# HSM_HSM_PKA_CE010000h register map
Vendor: Texas Instruments
Peripheral module from a debugger description file (folder AM263X).
Registers are 32-bit, read-write, reset 0x0 unless marked. A register's access mark holds for its fields unless they carry their own. Offsets are as the file gives them; lines under a group give offsets from that group; [hi:lo] are bit positions; {n}, {i} and the like mark numbered series; 'fields as' and 'values as' point back to an identical list; <NAME> marks a mode.

## HSM_PKA
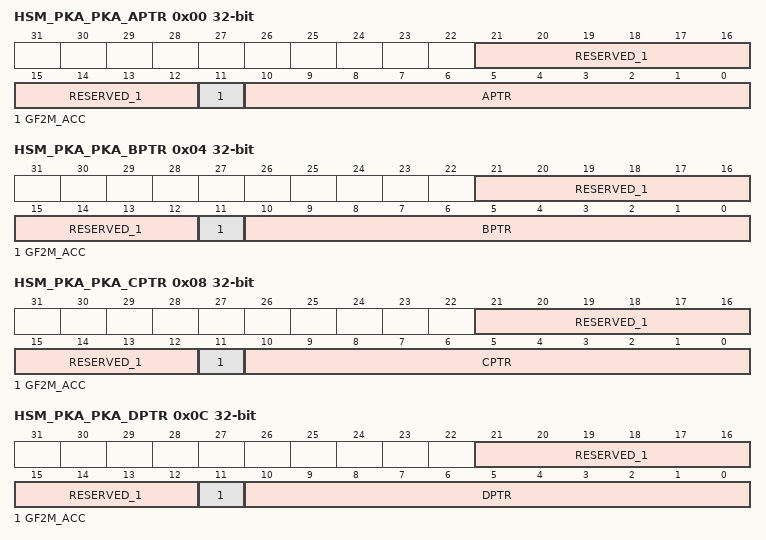
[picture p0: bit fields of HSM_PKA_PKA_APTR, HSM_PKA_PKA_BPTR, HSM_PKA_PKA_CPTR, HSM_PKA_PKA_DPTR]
0x00 HSM_PKA_PKA_APTR access per field — A operand address offset.
  [21:12] RESERVED_1 wo — Set to zero on Write, ignore on Read.
  [11] GF2M_ACC rw — When set, this bit specifies that Vector A is located within the operand registers of the GF2m Engine.
  [10:0] APTR rw — These bits specify the location of Vector A within the PKA RAM. Vectors are identified through the location of their least-significant 32-bit word. Note that bit [0] must be zero to ensure that the vector starts at an 8-byte boundary.
0x04 HSM_PKA_PKA_BPTR access per field — B operand address offset.
  [21:12] RESERVED_1 wo — Set to zero on Write, ignore on Read.
  [11] GF2M_ACC rw — When set, this bit specifies that Vector B is located within the operand registers of the GF2m Engine.
  [10:0] BPTR rw — These bits specify the location of Vector B within the PKA RAM. Vectors are identified through the location of their least-significant 32-bit word. Note that bit [0] must be zero to ensure that the vector starts at an 8-byte boundary.
0x08 HSM_PKA_PKA_CPTR access per field — C operand/result address offset.
  [21:12] RESERVED_1 wo — Set to zero on Write, ignore on Read.
  [11] GF2M_ACC rw — When set, this bit specifies that Vector C is located within the operand registers of the GF2m Engine.
  [10:0] CPTR rw — These bits specify the location of Vector C within the PKA RAM. Vectors are identified through the location of their least-significant 32-bit word. Note that bit [0] must be zero to ensure that the vector starts at an 8-byte boundary.
0x0C HSM_PKA_PKA_DPTR access per field — D operand/result address offset.
  [21:12] RESERVED_1 wo — Set to zero on Write, ignore on Read.
  [11] GF2M_ACC rw — When set, this bit specifies that Vector D is located within the operand registers of the GF2m Engine.
  [10:0] DPTR rw — These bits specify the location of Vector D within the PKA RAM. Vectors are identified through the location of their least-significant 32-bit word. Note that bit [0] must be zero to ensure that the vector starts at an 8-byte boundary.
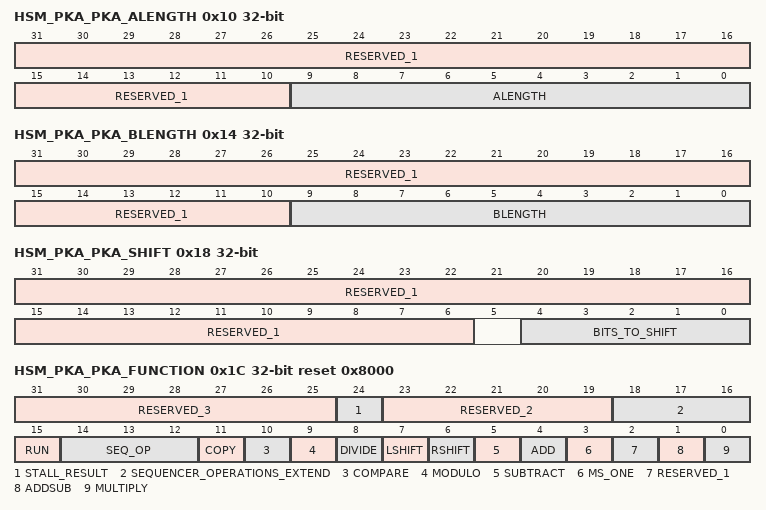
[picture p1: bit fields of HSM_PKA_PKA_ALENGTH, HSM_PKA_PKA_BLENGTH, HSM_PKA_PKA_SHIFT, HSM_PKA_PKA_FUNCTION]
0x10 HSM_PKA_PKA_ALENGTH access per field — Length of A operand.
  [31:10] RESERVED_1 wo — Set to zero on Write, ignore on Read.
  [9:0] ALENGTH rw — This register specifies the length [in 32-bit words] of Vector A.
0x14 HSM_PKA_PKA_BLENGTH access per field — Length of B operand.
  [31:10] RESERVED_1 wo — Set to zero on Write, ignore on Read.
  [9:0] BLENGTH rw — This register specifies the length [in 32-bit words] of Vector A.
0x18 HSM_PKA_PKA_SHIFT access per field — Bits to shift.
  [31:6] RESERVED_1 wo — Set to zero on Write, ignore on Read.
  [4:0] BITS_TO_SHIFT rw — This register specifies the number of bits to shift the input vector [in the range 0- 31] during a Rshift or Lshift operation
0x1C HSM_PKA_PKA_FUNCTION access per field reset 0x8000 — Function code, Run control/status, Stall Result control.
  [31:25] RESERVED_3 wo — Set to zero on Write, ignore on Read
  [24] STALL_RESULT rw — When written with a1b updating of the PKA_COMPARE, PKA_MSW and PKA_DIVMSW registers, as well as resetting the Run bit is stalled beyond the point that a running operation is actually finished. Use this to allow software enough time to read results from a previous operation when the newly started operation is known to take only a short amount of time. If a result is waiting, the result registers is updated and the Run bit is reset in the clock cycle following Writing the Stall Result bit back to0b The Stall result function may only be used for basic PKCP operations
  [23:19] RESERVED_2 wo — Set to zero on Write, ignore on Read.
  [18:16] SEQUENCER_OPERATIONS_EXTEND rw — These bits are an extend of bits [14:12] to select the complex Sequencer operation to perform
  [15] RUN rw — The host sets this bit to instruct the PKA module to begin processing the basic PKCP or complex Sequencer operation. This bit is reset low automatically when the operation is complete. The complement of this bit is available as interrupt see sections 5.6.5 and 5.6.6. After a reset, the Run bit is always set to1b Depending on the configuration, Program ROM or Program RAM, the following applies: Program ROM The first Sequencer instruction sets the bit to0b This is done immediately after the hardware reset is released. Program RAM The Sequencer needs to set the bit to0b As a valid firmware may not have been loaded, the Sequencer is held in software reset after the hardware reset is released [the Reset bit in PKA_SEQ_CRTL is set to1b. After the FW image is loaded and the Reset bit is cleared, the Sequencer starts to execute the FW. The first instruction clears the Run bit. In both cases a few clock cycles are needed before the first instruction is executed and the Run bit state has been propagated
  [14:12] SEQ_OP rw — These bits in combination with bits [18:16] select the complex Sequencer operation to perform
  [11] COPY rw — Perform copy operation.
  [10] COMPARE rw — Perform compare operation
  [9] MODULO rw — Perform modulo operation.
  [8] DIVIDE rw — Perform divide operation.
  [7] LSHIFT rw — Perform left shift operation.
  [6] RSHIFT rw — Perform right shift operation
  [5] SUBTRACT rw — Perform subtract operation
  [4] ADD rw — Perform add operation
  [3] MS_ONE rw — Loads the location of the Most Significant one bit within the result word indicated in the PKA_MSW register into bits [4:0] of the PKA_DIVMSW register - can only be used with basic PKCP operations8 , except for Divide, Modulo and Compare.
  [2] RESERVED_1 wo — Set to zero on Write, ignore on Read
  [1] ADDSUB rw — Perform combined Add/Subtract operation
  [0] MULTIPLY rw — Perform multiply operation.
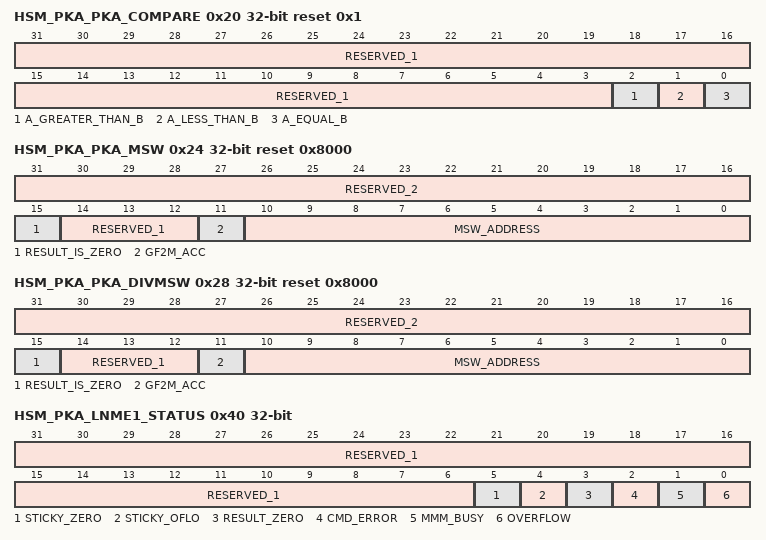
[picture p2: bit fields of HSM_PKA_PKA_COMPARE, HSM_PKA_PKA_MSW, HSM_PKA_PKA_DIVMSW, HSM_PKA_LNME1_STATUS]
0x20 HSM_PKA_PKA_COMPARE access per field reset 0x1 — Result of compare.
  [31:3] RESERVED_1 wo — Ignore on Read.
  [2] A_GREATER_THAN_B ro — Vector_A is greater than Vector_B.
  [1] A_LESS_THAN_B ro — Vector_A is less than Vector_B.
  [0] A_EQUAL_B ro — Vector_A is equal to Vector_B.
0x24 HSM_PKA_PKA_MSW access per field reset 0x8000 — MS non-zero word address.
  [31:16] RESERVED_2 wo — Ignore on Read.
  [15] RESULT_IS_ZERO ro — The result vector is all zeroes; ignore the address returned in bits [10:0].
  [14:12] RESERVED_1 wo — Ignore on Read.
  [11] GF2M_ACC ro — When set, this bit specifies that the result vector is located within the operand registers of the GF2m Engine.
  [10:0] MSW_ADDRESS ro — Address of the most significant non-zero 32-bit word of the result vector in PKA RAM.
0x28 HSM_PKA_PKA_DIVMSW access per field reset 0x8000 — MS non-zero word address for remainder (MOD and DIV ops).
  [31:16] RESERVED_2 wo — Ignore on Read.
  [15] RESULT_IS_ZERO ro — The result vector is all zeroes; ignore the address returned in bits [10:0].
  [14:12] RESERVED_1 wo — Ignore on Read.
  [11] GF2M_ACC ro — When set, this bit specifies that the result vector is located within the operand registers of the GF2m Engine.
  [10:0] MSW_ADDRESS ro — The description of the bits in this field depends on the value of the MS one bit in PKA_FUNCTION register. When MS one bit is0b Msw_Address[10:0] Address of the most significant non-zero 32-bit word of the Remainder result vector in PKA RAM. When MS one bit is1b Msw_bit_position[4:0] Reports the bit number of the most significant non-zero bit in the most significant non-zero word in PKA RAM. Remaining bits [10:5] are reserved.
0x40 HSM_PKA_LNME1_STATUS access per field — LNME 1 status register.
  [31:6] RESERVED_1 wo — Bits should be written with 0 and should be ignored on a read.
  [5] STICKY_ZERO rw — Read/write, reset value0b set to1bby hardware when the result of an MMM* or EXP operation is equal to zero or equal to the modulus N. Updated at the end of an operation [setonly], not cleared to0bby hardware on start of any operation [must be cleared by whoever is controlling the LNME]. Updating this bit is optional when requesting a 'fast ' MMM3A operation via the LNME_FAST_MMM register
  [4] STICKY_OFLO rw — Read/write, reset value0b set to1bby hardware when the result of an MMM* or EXP operation is equal to- or greater than the modulus N. Updated at the end of an operation [setonly], not cleared to0bby hardware on start of any operation [must be cleared by whoever is controlling the LNME]. Updating this bit is optional when requesting a 'fast ' MMM3A operation via the LNME_FAST_MMM register.
  [3] RESULT_ZERO rw — Read/write, reset value0b set to1bby hardware when the result of an MMM* or EXP operation is equal to zero or equal to the modulus N. Updated at the end of an operation, automatically cleared to0bby hardware on start of any operation
  [2] CMD_ERROR rw — Read/write, reset value0b set to1bby hardware when trying to start multiple operations in one command, automatically cleared to0bby hardware on start of any [legal] operation
  [1] MMM_BUSY rw — Read/write, reset value0b set to1bby hardware when the LNME executes an MMM* or EXP operation [cannot be written to0bduring execution of an operation]. Automatically cleared to0bby hardware when finishing an operation. The LNME interrupt is the complement of this bit and can be controlled directly for testing purposes when no actual operation is busy.
  [0] OVERFLOW rw — Read/write, reset value0b set to1bby hardware when the result of an MMM* or EXP operation is equal to- or greater than the modulus N. Updated at the end of an operation, automatically cleared to0bby hardware on start of any operation
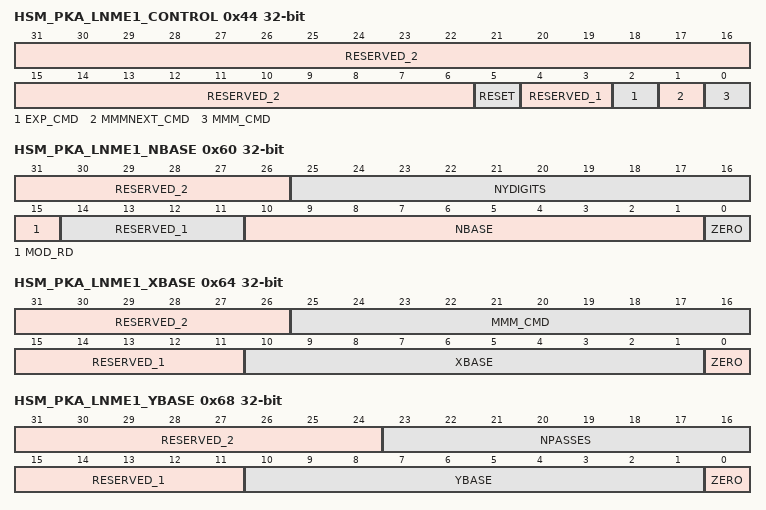
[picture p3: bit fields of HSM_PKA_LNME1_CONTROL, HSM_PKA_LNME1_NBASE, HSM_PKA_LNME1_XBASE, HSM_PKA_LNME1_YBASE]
0x44 HSM_PKA_LNME1_CONTROL access per field — LNME 1 control register (no SW reset).
  [31:6] RESERVED_2 wo — Bits should be written with 0 and should be ignored on a read.
  [5] RESET rw — Set-only, reset value0b When set to1b the LNME is reset and all internal storage locations are flushed [including the LNME FIFO RAM[s]], cleared to0bby hardware at the end of the operation. This command has priority over the MMM* and EXP commands and can abort those in mid-execution. Note: Bit [5] is 'Reserved ' in the LNME1_CONTROL register. For a dual LNME, the 'reset ' bit in the LNME0_CONTROL register controls the software reset in both LNMEs
  [4:3] RESERVED_1 wo — Bits should be written with 0 and should be ignored on a read. For backward compatibility, these bits are actually connected to flip-flops.
  [2] EXP_CMD rw — Set-only, reset value0b When set to1b the LNME starts an EXP operation; cleared to0bby hardware at the end of the operation or when executing a RESET command
  [1] MMMNEXT_CMD rw — Set-only, reset value0b When set to1b the LNME starts an MMMNEXT operation; cleared to0bby hardware at the end of the operation or when executing a RESET command. Note: Setting bits [1] and [0] at the same time starts an MMM3A operation, whereby the result of the MMM operation is written to the offset in PKA data RAM specified by the bbase field in the LNME*_BBASE register. These bits are cleared to 0 by hardware at the end of the operation or when executing a RESET command.
  [0] MMM_CMD rw — Set-only, reset value0b When set to1b the LNME starts an MMM operation; cleared to0bby hardware at the end of the operation or when executing a RESET command.
0x60 HSM_PKA_LNME1_NBASE access per field — N-Operand BASE Address, Y-Operand and N-Operand 32-bit 'Digits '
  [31:26] RESERVED_2 wo — Bits should be written with 0 and should be ignored on a read
  [25:16] NYDIGITS rw — Y-Operand and N-Operand 32-bit'digits' [offset by 1]. Also used for X-operand length in an EXP operation. Minimum value is 0 [for 32 bit operands], maximum value is 12810 [for4128bit operands, actually4096'real ' data bits plus 32 bits to handle inputs and results higher than the4096bits modulus value].
  [15] MOD_RD rw — Setting this bit to1bindicates that the modulus should be read from the GF2m Engine 's GF2M_OPERAND_A_0..15 [bits [511:0]] and GF2M_OPERAND_B_0..7 [bits [767:512]] registers. Note: When this bit is set, the nbase field contents become 'don 't care '.
  [14:11] RESERVED_1 wo — Bits should be written with 0 and should be ignored on a read.
  [10:1] NBASE rw — N-Operand Base Address.
  [0] ZERO ro — Bit [0] is forced to 0 to locate the first 32 bits word at a 64 bit word boundary.
0x64 HSM_PKA_LNME1_XBASE access per field — X-Operand BASE Address, X-Operand 32-bit 'Digits '.
  [31:26] RESERVED_2 wo — Bits should be written with 0 and should be ignored on a read.
  [25:16] MMM_CMD rw — X-Operand 32-bit'digits' [offset by 1], used for MMM* operations only. Minimum value is 0 [for 32 bit X operands], maximum value is 12811 [for4128bit X operands, actually4096'real ' data bits plus 2 extra bits to handle X inputs up to four times the4096bits modulus value, plus 30 dummy data bits to fill out the last word which should all be 0].
  [15:11] RESERVED_1 wo — Bits should be written with 0 and should be ignored on a read.
  [10:1] XBASE rw — X-Operand Base Address.
  [0] ZERO ro — Bit [0] is forced to 0 to locate the first 32 bits word at a 64 bit word boundary.
0x68 HSM_PKA_LNME1_YBASE access per field — Y-Operand BASE Address, MMM Passes.
  [31:24] RESERVED_2 wo — Bits should be written with 0 and should be ignored on a read.
  [23:16] NPASSES rw — MMM passes. Minimum value is 0 [for ONE pass], maximum value is 255 for 256 passes.
  [15:11] RESERVED_1 wo — Bits should be written with 0 and should be ignored on a read.
  [10:1] YBASE rw — Y-Operand Base Address.
  [0] ZERO ro — Bit [0] is forced to 0 to locate the first 32 bits word at a 64 bit word boundary.
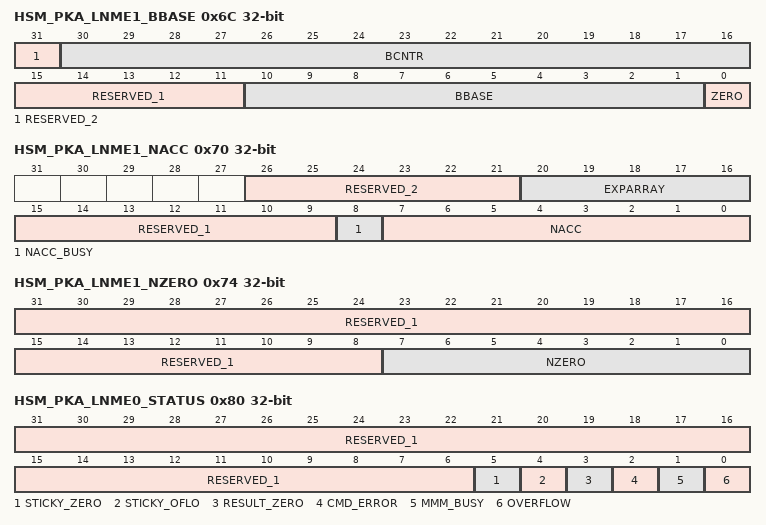
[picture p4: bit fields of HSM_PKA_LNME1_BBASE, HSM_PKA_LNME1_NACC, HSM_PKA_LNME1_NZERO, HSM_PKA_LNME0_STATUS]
0x6C HSM_PKA_LNME1_BBASE access per field — B-Operand BASE Address, B-Operand Bit Count.
  [31] RESERVED_2 wo — Bits should be written with 0 and should be ignored on a read.
  [30:16] BCNTR rw — B-Operand Bit Count. Minimum value is 0 for an exponent length of 2 bits, maximum value is 409513 for an exponent of4097bits [to allow exponent blinding]. If no exponent blinding is used the exponent would normally be smaller than the modulus. Note that the most significant B operand bit need not be stored in memory and is always assumed to be1b
  [15:11] RESERVED_1 wo — Bits should be written with 0 and should be ignored on a read.
  [10:1] BBASE rw — B-Operand BASE Address.
  [0] ZERO ro — Bit [0] is forced to 0 to locate the first 32 bits word at a 64 bit word boundary.
0x70 HSM_PKA_LNME1_NACC access per field — N ', N ' calculation busy flag, exponent array size for EXP.
  [26:21] RESERVED_2 wo — Bits should be written with 0 and should be ignored on a read.
  [20:16] EXPARRAY rw — Exponent Array. A minimum [default] value of 0 indicates that there is only odd power: AR mod N. This is the value of exparray when exponent re-coding is not used. A maximum value of 31 indicates 32 odd powers can be used for exponent re-coding, this includes A1R mod N as the first 'odd power '.
  [15:9] RESERVED_1 wo — Bits should be written with 0 and should be ignored on a read.
  [8] NACC_BUSY rw — Reset-only - nacc Calculation Busy, set to1bduring 8 clock cycles after Writing nzero in LNME*_NZERO while nacc is being calculated. During this time, operation starts are stalled. Writing this bit with0baborts the calculation but can leave nacc in an unknown state [Writing NACC while resetting nacc_busy prevents this].
  [7:0] NACC rw — N Accent. Any odd [bit [0] is1b 8 bit value can be loaded here [result of calculation]. Automatically loaded with calculated value after Writing nzero in LNME*_NZERO.
0x74 HSM_PKA_LNME1_NZERO access per field — Lowest byte of N-Operand for N ' calculation.
  [31:8] RESERVED_1 wo — Bits should be written with 0 and should be ignored on a read.
  [7:0] NZERO rw — N vector Byte 0. Any odd [bit [0] is1b 8 bit value can be loaded here. Writing starts the nacc calculation automatically.
0x80 HSM_PKA_LNME0_STATUS access per field — LNME 0 status register.
  fields as HSM_PKA_LNME1_STATUS
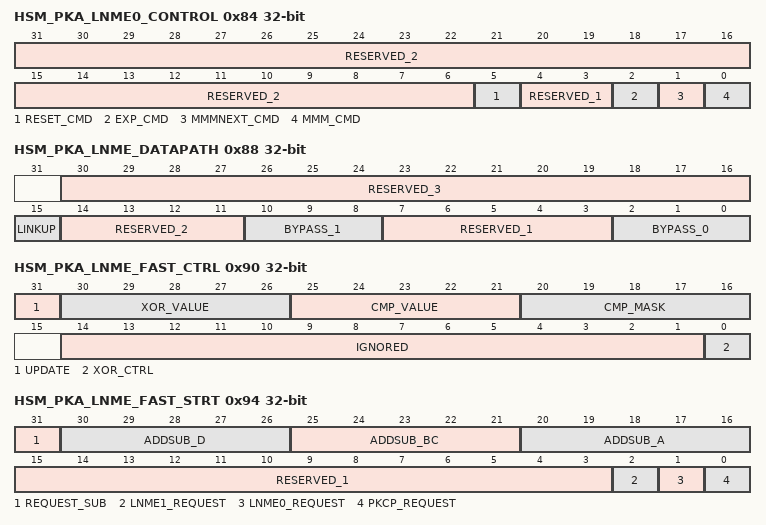
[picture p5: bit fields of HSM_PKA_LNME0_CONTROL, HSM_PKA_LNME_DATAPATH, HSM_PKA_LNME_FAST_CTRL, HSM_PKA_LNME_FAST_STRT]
0x84 HSM_PKA_LNME0_CONTROL access per field — LNME 0 control register.
  [31:6] RESERVED_2 wo — Bits should be written with 0 and should be ignored on a read.
  [5] RESET_CMD rw — Set-only, reset value0b When set to1b the LNME is reset and all internal storage locations are flushed [including the LNME FIFO RAM[s]], cleared to0bby hardware at the end of the operation. This command has priority over the MMM* and EXP commands and can abort those in mid-execution. Note: Bit [5] is 'Reserved ' in the LNME1_CONTROL register. For a dual LNME, the 'reset ' bit in the LNME0_CONTROL register controls the software reset in both LNMEs
  [4:3] RESERVED_1 wo — Bits should be written with 0 and should be ignored on a read. For backward compatibility, these bits are actually connected to flip-flops.
  [2] EXP_CMD rw — Set-only, reset value0b When set to1b the LNME starts an EXP operation; cleared to0bby hardware at the end of the operation or when executing a RESET command
  [1] MMMNEXT_CMD rw — Set-only, reset value0b When set to1b the LNME starts an MMMNEXT operation; cleared to0bby hardware at the end of the operation or when executing a RESET command. Note: Setting bits [1] and [0] at the same time starts an MMM3A operation, whereby the result of the MMM operation is written to the offset in PKA data RAM specified by the bbase field in the LNME*_BBASE register. These bits are cleared to 0 by hardware at the end of the operation or when executing a RESET command.
  [0] MMM_CMD rw — Set-only, reset value0b When set to1b the LNME starts an MMM operation; cleared to0bby hardware at the end of the operation or when executing a RESET command.
0x88 HSM_PKA_LNME_DATAPATH access per field — PE bypass and dual LNME linking control.
  [30:16] RESERVED_3 wo — Bits should be written with 0 and should be ignored on a read.
  [15] LINKUP rw — This bit controls the 'linking ' of the two LNME PE chains in a dual LNME [if configured, otherwise this field must be treated as 'Reserved ']. When set to1b all PEs of the 2nd chain are inserted at the end of the 1st chain [in front of the 'terminating PE '], the X-FIFOs are combined into one and the LNME FIFO memories are combined to form a dual depth FIFO.Note: This bit cannot be changed while an operation is busy in either the 1st or the 2nd LNME.
  [14:11] RESERVED_2 wo — Bits should be written with 0 and should be ignored on a read.
  [10:8] BYPASS_1 rw — This field controls the PE chain bypass multiplexers for the 2nd LNME. The number of bits is 3 for 12-PE configurations.Note: This field cannot be changed while an operation is busy in the 2nd LNME.
  [7:3] RESERVED_1 wo — Bits should be written with 0 and should be ignored on a read.
  [2:0] BYPASS_0 rw — This field controls the PE chain bypass multiplexers for the 1st LNME. The number of bits is 3 for 12-PE configurations.Note: This field cannot be changed while an operation is busy in the 1st LNME.
0x90 HSM_PKA_LNME_FAST_CTRL — Fast MMM3A/ADDSUB op control.
  [31] UPDATE — Write-only, bit should be written with1bwhen updating bits [30:16], always reads0b When Writing this bit with a0b bits [30:16] will not be changed irrespective the values written there. Updating bits [30:16] can only be done with a single write action, separate Byte writes are not possible.
  [30:26] XOR_VALUE — This field controls the value XOR-ed into the vector index fields of the LNME_FAST_MMM and LNME_FAST_STRT registers when the xor_ctrl is1bupon starting an MMM3A and/or PKCP ADDSUB operation using those registers. The actual XOR is only done when a vector index field equals the cmp_value field in the bits that are1bin the cmp_mask field. To modify this field, the update bit should be written with a1b
  [25:21] CMP_VALUE — This field contains bits that are compared against the vector index fields of the LNME_FAST_MMM and LNME_FAST_STRT registers when starting an MMM3A and/or PKCP ADDSUB operation using those registers. Comparison is only done for the corresponding1bbits in the cmp_mask field, other bits are don 't care. To modify this field, the update bit should be written with a 1b
  [20:16] CMP_MASK — This field controls which bits of the vector index fields of the LNME_FAST_MMM and LNME_FAST_STRT registers are compared against cmp_value when starting an MMM3A and/or PKCP ADDSUB operation using those registers. A1bin this field compares the corresponding bit in the cmp_value field; a0bin this field makes the corresponding cmp_value bit a don 't care. To modify this field, the update bit should be written with a1b
  [14:1] IGNORED — These bits are ignored on a write and will read zero on a read. These bits are intended to allow Writing any value to bits [15:1] while setting the xor_ctrl bit
  [0] XOR_CTRL — This bit controls whether or not the value in the xor_mask field is XOR-ed into the vector index fields of the LNME_FAST_MMM and LNME_FAST_STRT registers. The state of this bit is logged with an MMM3A or ADDSUB operation request using those registers and may be changed immediately after that point.
0x94 HSM_PKA_LNME_FAST_STRT access per field — Fast ADDSUB operation start (in PKCP).
  [31] REQUEST_SUB rw — This bit controls which operation is actually performed in the PKCP:A0brequests an ADD operation, which is performed using the ADDSUB A+C-B operation, with the A and C vectors controlled by the addsub_a and addsub_bc fields here. The B vector of the PKCP should point to a suitable vector containing the value zero. As both the input vectors can be up to 2 times the Modulus in value, the result can be close to 4 times the Modulus vector value.A1brequests a SUB operation, which is performed using the ADDSUB A+C-B operation, with the A and B vectors controlled by the addsub_a and addsub_bc fields here. The C vector of the PKCP should point to a suitable vector containing 2 times the Modulus value. As both the input vectors can be up to 2 times the Modulus in value, the result can be close to 4 times the Modulus vector value [in case A is at its maximum value and B equals zero].
  [30:26] ADDSUB_D rw — This holds the index for the PKCP ADDSUB result vector 'D ' in the table [before possible XOR-ing with the xor_value field in the LNME_FAST_CTRL register].
  [25:21] ADDSUB_BC rw — This holds the index for the PKCP ADDSUB operation 'B ' or 'C ' input vector in the table [before possible XOR-ing with the xor_value field in the LNME_FAST_CTRL register].
  [20:16] ADDSUB_A rw — This holds the index for the PKCP ADDSUB operation 'A ' input vector in the table [before possible XOR-ing with the xor_value field in the LNME_FAST_CTRL register].
  [15:3] RESERVED_1 wo — Bits should be written with 0 and should be ignored on a read.
  [2] LNME1_REQUEST rw — This bit will be set to1bwhen an MMM3A operation is requested in the 2nd LNME by Writing to bits [31:16] of the LNME_FAST_MMM register with a non-zero value. The operation is started as soon as possible, i.e. when both LNMEs and the PKCP are ready for a next operation - if an operation was already busy in the 2nd LNME, the LNME1 interrupt may only activate for a single clock cycle. This bit automatically falls back to0bwhen the operation is actually started, at which point both the mmm and mmm_next bits in the LNME1_CTRL register are set to1b To abort this request, write this bit with a1b- Writing a0bhas no effect.Note: This bit is 'Reserved ' in a normal [non-dual] LNME configuration.
  [1] LNME0_REQUEST rw — This bit will be set to1bwhen an MMM3A operation is requested in the 1st LNME by Writing to bits [15:0] of the LNME_FAST_MMM register with a non-zero value. The operation is started as soon as possible, i.e. when both LNMEs and the PKCP are ready for a next operation - if an operation was already busy in the 1st LNME, the LNME0 interrupt may only activate for a single clock cycle. This bit automatically falls back to0bwhen the operation is actually started, at which point both the mmm and mmm_next bits in the LNME0_CTRL register are set to1b To abort this request, write this bit with a1b- Writing a0bhas no effect.
  [0] PKCP_REQUEST rw — This bit will be set to1bwhen an ADDSUB operation is requested in the PKCP by Writing to bits [31:16] of this register with a non-zero value. The operation is started as soon as possible, i.e. when both LNMEs and the PKCP are ready for a next operation. This bit automatically falls back to0bwhen the operation is actually started. To abort this request, write this bit with a1b- Writing a0bhas no effect.
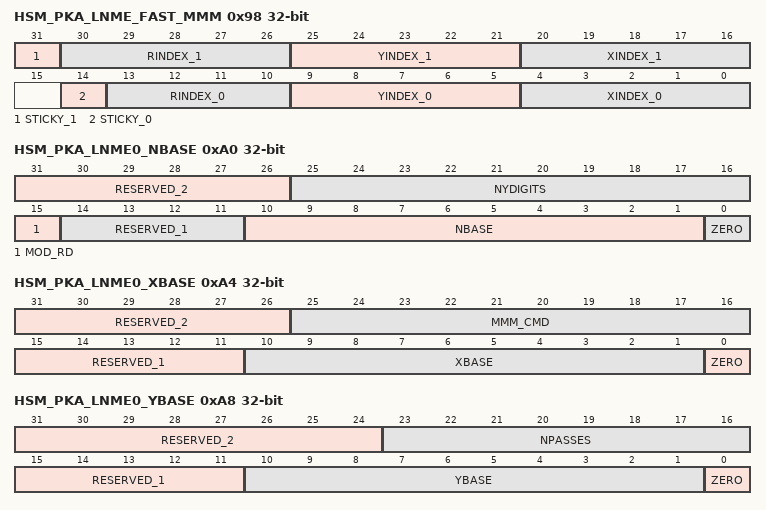
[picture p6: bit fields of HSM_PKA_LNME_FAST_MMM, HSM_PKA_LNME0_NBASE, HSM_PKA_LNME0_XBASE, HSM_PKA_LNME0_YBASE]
0x98 HSM_PKA_LNME_FAST_MMM — Fast MMM3A operation start.
  [31] STICKY_1 — Bit should be written with1bto request updating the sticky_oflo and sticky_zero status bits in the LNME1_STATUS register. When this bit is written0b those status bits are not modified at the end of the MMM3A operation. Note: This field is 'Reserved ' in a normal [non-dual] LNME configuration.
  [30:26] RINDEX_1 — This holds the index for the 2nd LNME 's result vector in the table [before possible XOR-ing with the xor_value field in the LNME_FAST_CTRL register]. Note: This field is 'Reserved ' in a normal [non-dual] LNME configuration.
  [25:21] YINDEX_1 — This holds the index for the 2nd LNME 's Y input vector in the table [before possible XOR-ing with the xor_value field in the LNME_FAST_CTRL register]. Note: This field is 'Reserved ' in a normal [non-dual] LNME configuration.
  [20:16] XINDEX_1 — This holds the index for the 2nd LNME 's X input vector in the table [before possible XOR-ing with the xor_value field in the LNME_FAST_CTRL register]. Note: This field is 'Reserved ' in a normal [non-dual] LNME configuration.
  [14] STICKY_0 — Bit should be written with1bto request updating the sticky_oflo and sticky_zero status bits in the LNME0_STATUS register. When this bit is written0b those status bits are not modified at the end of the MMM3A operation.
  [13:10] RINDEX_0 — This holds the index for the 1st LNME 's result vector in the table [before possible XOR-ing with the xor_value field in the LNME_FAST_CTRL register].
  [9:5] YINDEX_0 — This holds the index for the 1st LNME 's Y input vector in the table [before possible XOR-ing with the xor_value field in the LNME_FAST_CTRL register].
  [4:0] XINDEX_0 — This holds the index for the 1st LNME 's X input vector in the table [before possible XOR-ing with the xor_value field in the LNME_FAST_CTRL register].
0xA0 HSM_PKA_LNME0_NBASE access per field — N-Operand BASE Address, Y-Operand and N-Operand 32-bit 'Digits '
  fields as HSM_PKA_LNME1_NBASE
0xA4 HSM_PKA_LNME0_XBASE access per field — X-Operand BASE Address, X-Operand 32-bit 'Digits '.
  fields as HSM_PKA_LNME1_XBASE
0xA8 HSM_PKA_LNME0_YBASE access per field — Y-Operand BASE Address, MMM Passes.
  fields as HSM_PKA_LNME1_YBASE
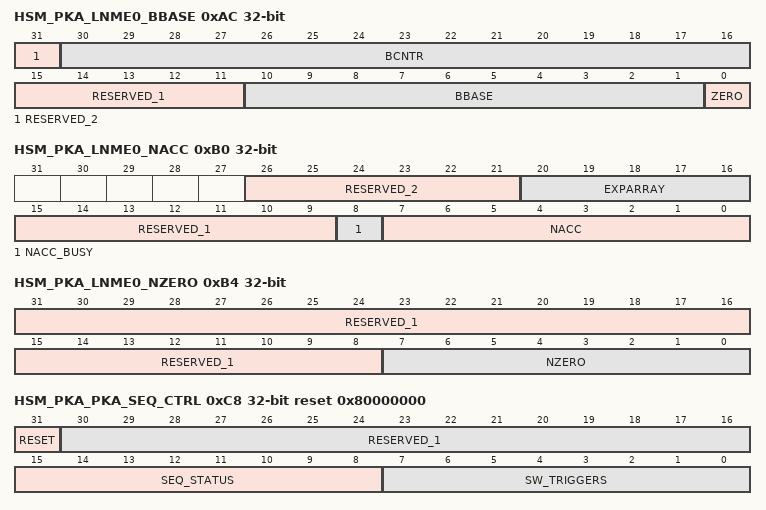
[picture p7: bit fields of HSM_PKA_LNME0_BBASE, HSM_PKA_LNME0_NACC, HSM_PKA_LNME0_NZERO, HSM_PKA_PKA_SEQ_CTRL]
0xAC HSM_PKA_LNME0_BBASE access per field — B-Operand BASE Address, B-Operand Bit Count.
  fields as HSM_PKA_LNME1_BBASE
0xB0 HSM_PKA_LNME0_NACC access per field — N ', N ' calculation busy flag, exponent array size for EXP.
  fields as HSM_PKA_LNME1_NACC
0xB4 HSM_PKA_LNME0_NZERO access per field — Lowest byte of N-Operand for N ' calculation.
  fields as HSM_PKA_LNME1_NZERO
0xC8 HSM_PKA_PKA_SEQ_CTRL access per field reset 0x80000000 — PKA Sequencer control/status register.
  [31] RESET rw — Read/Write, reset value0b[ZERO]. Writing1bwill reset the Sequencer, write to0bto restart operations again. As the reset value is0b the Sequencer will automatically start operations executing from program ROM. This bit should always be written with zero and ignored when Reading this register. Read/Write, reset value1b[ONE]. When1b the Sequencer is held in a reset state and the PKA_PROGRAM area is accessible for loading the Sequencer program [while the PKA_DATA_RAM is inaccessible], write to0bto [re]start Sequencer operations and disable PKA_PROGRAM area accessibility [also enables the PKA_DATA_RAM accesses]. Resetting the Sequencer [in order to load other firmware] should only be done when the PKA Engine is not performing any operations [i.e. the Run bit in the PKA_FUNCTION register should be zero].
  [30:16] RESERVED_1 wo — Bits should be written with 0 and should be ignored on a read.
  [15:8] SEQ_STATUS ro — These read-only bits can be used by the Sequencer to communicate status to the outside world. Bit [8] is also used as Sequencer interrupt, with the complement of this bit OR-ed into the 'Run ' bit in PKA_FUNCTION. Refer to the SafeXcel-IP-29t2 Programmer Manual [3] for the firmware encoding of these status bits. This field should always be written with zeroes.
  [7:0] SW_TRIGGERS rw — These bits can be used by software to trigger Sequencer operations. External logic can set these bits by Writing a1b can not reset them by Writing a0b The Sequencer can reset these bits by Writing a0b can not set them by Writing a1b Setting the Run bit in PKA_FUNCTION together with a non-zero Sequencer operations field automatically sets bit [0] here [firmware functionality]. Refer to the SafeXcel-IP-29t2 Programmer Manual [3] for the firmware definition of these bits.
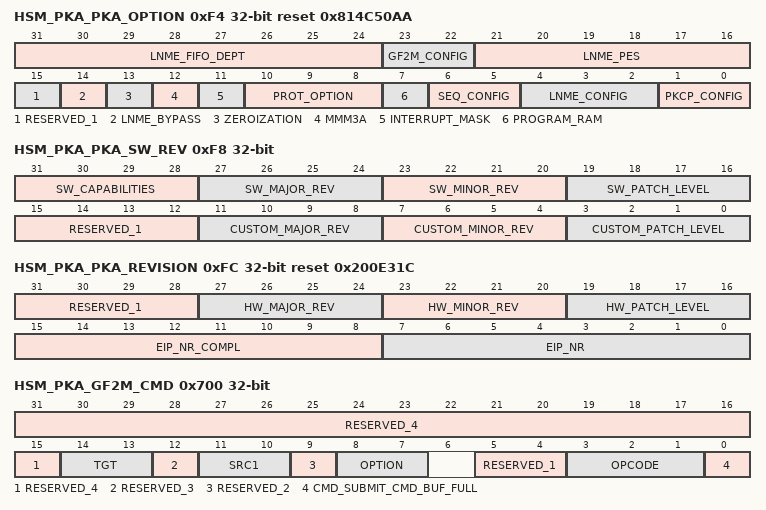
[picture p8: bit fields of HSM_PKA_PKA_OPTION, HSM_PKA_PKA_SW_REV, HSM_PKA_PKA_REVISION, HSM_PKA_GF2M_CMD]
0xF4 HSM_PKA_PKA_OPTION access per field reset 0x814C50AA — PKA HW options register.
  [31:24] LNME_FIFO_DEPT ro — Number of words in the LNME 's FIFO RAM, should be ignored if LNME configuration is 0.
  [23:22] GF2M_CONFIG ro — Value 0 indicates NO GF2m Engine, value 1 indicates one standard GF2m Engine [field size 571 bits, mul_depth = 4], other values are reserved.
  [21:16] LNME_PES ro — Number of Processing Elements in the pipeline of the LNME, should be ignored if LNME configuration is 0.
  [15] RESERVED_1 wo — Ignore on Read.
  [14] LNME_BYPASS ro — Value1bindicates that bypass logic is present in the PEs.
  [13] ZEROIZATION ro — Value1bindicates that hardware zeroization logic is present.
  [12] MMM3A ro — Value1bindicates that the LNME, supports the MMM3A operation.
  [11] INTERRUPT_MASK ro — Value0bindicates that the main interrupt output [bit [0] of the PKA_IRQSTATUS register] is the direct complement of the Run bit in the PKA_CONTROL register, value1bindicates that interrupt masking logic is present for this output.
  [10:8] PROT_OPTION ro — Value 0 indicates no additional protection against side channel attacks, value 1 indicates the 'SCAP ' option, value 3 indicates the 'PROT ' option, other values reserved.
  [7] PROGRAM_RAM ro — Value1bindicates Sequencer program storage in RAM, value0bin ROM.
  [6:5] SEQ_CONFIG ro — Value 1 indicates a standard Sequencer, other values reserved.
  [4:2] LNME_CONFIG ro — Value 0 indicates NO LNME. Value 1 indicates one standard LNME [with alpha = 32, beta = 8]. Value 2 indicates a dual LNME [with alpha = 32, beta = 8]. Other values are reserved.
  [1:0] PKCP_CONFIG ro — Value 1 indicates a PKCP with a 16x16 multiplier, value 2 indicates a PKCP with a 32x32 multiplier, other values reserved.
0xF8 HSM_PKA_PKA_SW_REV access per field — PKA firmware revision and capabilities register.
  [31:28] SW_CAPABILITIES ro — 4 bits binary encoding for the functionality implemented in the firmware. Refer to the SafeXcel-IP-29t2 Programmer Manual [3] for the firmware capabilities and the encoding of these bits.
  [27:24] SW_MAJOR_REV ro — 4 bits binary encoding of the Authentec internal major firmware revision number.
  [23:20] SW_MINOR_REV ro — 4 bits binary encoding of the Authentec internal minor firmware revision number.
  [19:16] SW_PATCH_LEVEL ro — 4 bits binary encoding of the Authentec internal firmware patch level, initial release will carry value zero. Patches are used to remove bugs without changing the functionality or interface of a module - see the release notes delivered with the package.
  [15:12] RESERVED_1 wo — Bits should be ignored on a read.
  [11:8] CUSTOM_MAJOR_REV ro — 4 bits binary encoding of the TI specific major firmware revision number.
  [7:4] CUSTOM_MINOR_REV ro — 4 bits binary encoding of the TI specific minor firmware revision number.
  [3:0] CUSTOM_PATCH_LEVEL ro — 4 bits binary encoding of the TI specific firmware patch level, initial release will carry value zero. Patches are used to remove bugs without changing the functionality or interface of a module - see the release notes delivered with the package.
0xFC HSM_PKA_PKA_REVISION access per field reset 0x200E31C — PKA HW revision register.
  [31:28] RESERVED_1 wo — Bits should be ignored on a read.
  [27:24] HW_MAJOR_REV ro — 4 bits binary encoding of the major hardware revision number.
  [23:20] HW_MINOR_REV ro — 4 bits binary encoding of the minor hardware revision number.
  [19:16] HW_PATCH_LEVEL ro — 4 bits binary encoding of the hardware patch level, initial release will carry value zero. Patches are used to remove bugs without changing the functionality or interface of a module - see the release notes delivered with the package.
  [15:8] EIP_NR_COMPL ro — Bit-by-bit logic complement of bits [7:0], EIP-28 gives 0xE3.
  [7:0] EIP_NR ro — 8 bits binary encoding of the EIP number, EIP-28 gives 0x1C.
{0x400+4i} HSM_PKA_GF2M_OPERAND_A_{i} (i=0..16) — Operand A registers.
  [31:0] OPERAND_A — Operand A register [{32i+31}:{32i}]
0x444 HSM_PKA_GF2M_OPERAND_A_17 — Operand A registers.
  [27:0] OPERAND_A — Operand A register [571:544]
{0x480+4i} HSM_PKA_GF2M_OPERAND_B_{i} (i=0..16) — Operand B registers.
  [31:0] OPERAND_B — Operand B register [{32i+31}:{32i}]
0x4C4 HSM_PKA_GF2M_OPERAND_B_17 — Operand B registers.
  [27:0] OPERAND_B — Operand B register [571:544]
{0x500+4i} HSM_PKA_GF2M_OPERAND_C_{i} (i=0..16) — Operand C registers.
  [31:0] OPERAND_C — Operand C register [{32i+31}:{32i}]
0x544 HSM_PKA_GF2M_OPERAND_C_17 — Operand C registers.
  [27:0] OPERAND_C — Operand C register [571:544]
{0x580+4i} HSM_PKA_GF2M_OPERAND_D_{i} (i=0..16) — Operand D registers.
  [31:0] OPERAND_D — Operand D register [{32i+31}:{32i}]
0x5C4 HSM_PKA_GF2M_OPERAND_D_17 — Operand D registers.
  [27:0] OPERAND_D — Operand D register [571:544]
{0x600+4i} HSM_PKA_GF2M_POLYNOMIAL_{i} (i=0..16) — GF2M_POLYNOMIAL_{i}.
  [31:0] POLYNOMIAL — Polynomial register [{32i+31}:{32i}]
0x644 HSM_PKA_GF2M_POLYNOMIAL_17 — GF2M_POLYNOMIAL_17.
  [27:0] POLYNOMIAL — Polynomial register [571:544]
0x700 HSM_PKA_GF2M_CMD access per field — Command register.
  [31:15] RESERVED_4 wo — These bits should be written with zeroes and ignored on a read.
  [14:13] TGT rw — Target address1:00b= GF2M_OPERAND_A,01b= GF2M_OPERAND_B,10b= GF2M_OPERAND_C,11b= GF2M_OPERAND_D
  [12] RESERVED_3 wo — These bits should be written with zeroes and ignored on a read.
  [11:10] SRC1 rw — Source address1:00b= GF2M_OPERAND_A,01b= GF2M_OPERAND_B,10b= GF2M_OPERAND_C,11b= GF2M_OPERAND_D
  [9] RESERVED_2 wo — These bits should be written with zeroes and ignored on a read.
  [8:7] OPTION rw — Source address0:00b= GF2M_OPERAND_A,01b= GF2M_OPERAND_B,10b= GF2M_OPERAND_C,11b= GF2M_OPERAND_D
  [5:4] RESERVED_1 wo — These bits should be written with zeroes and ignored on a read.
  [3:1] OPCODE rw — Command opcode:000bClear tgt operand register.001bCopy src0 operand to tgt operand register.010bGF[2m] Add src0 and src1 operands, write result to tgt operand.011bGF[2m] Multilpy src0 and src1 operands, write result to tgt operand.100bShift-xor-loop operation to assist a GF[2m] Inverse operation. All other opcode combinations are reserved and should not be used. Refer to Table 19 for more detailed command information.
  [0] CMD_SUBMIT_CMD_BUF_FULL rw — Setting this bit [cmd_submit] submits the command that is specified by the remaining bits in this register. The cmd_submit bit is self clearing. Writing this bit with0bhas no effect. Submitting a command always sets the busy bit in GF2M_STAT. In case a second command is submitted while the engine is still busy processing, the command will be buffered internally. The cmd_buf_full bit - that is returned when Reading this bit location - will be set to indicate that command buffer is fully occupied. The cmd_buf_full bit reads0bwhen the GF2m Engine is ready to accept a new command. When this bit reads1b the command buffer is full and no new command may be written.
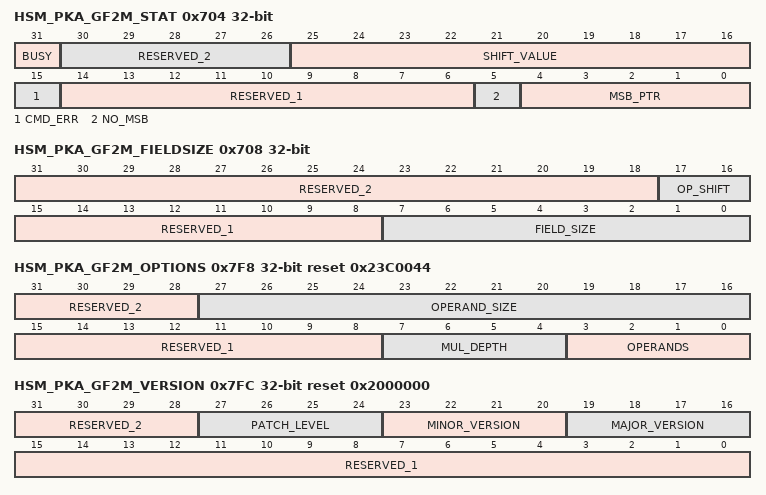
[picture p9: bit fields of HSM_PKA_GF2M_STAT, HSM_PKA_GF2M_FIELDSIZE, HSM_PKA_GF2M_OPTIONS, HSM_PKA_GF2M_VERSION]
0x704 HSM_PKA_GF2M_STAT access per field — Status register.
  [31] BUSY ro — This status bit reads1bwhen the GF2m Engine is processing a command. The irq output is the inverted level of this bit.
  [30:26] RESERVED_2 wo — These bits should be written with zeroes and ignored on a read.
  [25:16] SHIFT_VALUE ro — Represents the number of src0 operand right-shifts that was performed during the last 'shift-xor-loop ' operation. Note: In case the shift-xor-loop command did not find src0 bit [0] to become 'odd ' after [mul_rounds*mul_depth] cycles the shift_value reports 0x3ff, meaning 'invalid '.
  [15] CMD_ERR ro — Command error. Set to1bby hardware when trying to start a processing using a non-valid opcode. This bit is automatically cleared to0bby hardware on a start of any [legal] operation. The command error is also triggered when the shift-xor-loop command is executed with equal pointers in the src0 and src1 fields. Note: When the first command in a sequence of two commands [buffered commands] produces an error, the cmd_err bit remains active until the engine has finished processing, regardless if the second command was valid.
  [14:6] RESERVED_1 wo — These bits should be written with zeroes and ignored on a read.
  [5] NO_MSB ro — Result of the 'degree ' operation: If the last read operand word contains only zeroes, there is no MSB present in this word. In that case this bit will be1b
  [4:0] MSB_PTR ro — Result of the 'degree ' operation: Represents the index location of the MSB within the 32-bit operand word that was last read via the TCM interface.
0x708 HSM_PKA_GF2M_FIELDSIZE access per field — Field size register.
  [31:18] RESERVED_2 wo — These bits should be written with zeroes and ignored on a read.
  [17:16] OP_SHIFT rw — This field must be populated with the 'operand shift ' value for the GF[2m] multiplication operation. The operand shift value is the offset from the MSB with respect to the left-shift boundaries. The operand shift value can be determined using the following expression: operand_shift = field size%mul_depth. Examples for commonly used field sizes and a multiplier depth [mul_depth] value of4:163-bit: 2 'b11, 233-bit: 2 'b01, 283-bit: 2 'b11, 409-bit: 2 'b01, 571-bit: 2 'b11
  [15:8] RESERVED_1 wo — These bits should be written with zeroes and ignored on a read.
  [7:0] FIELD_SIZE rw — This field must be populated with the number of multiplier rounds for the GF[2m] operation. The number of multiplier rounds depends on the multiplier depth and the field size:mul_rounds = [field size/mul_depth]+1. The minimum value for this register is 0x1 and the maximum value 0x8F. Examples for commonly used field sizes and a multiplier depth [mul_depth] value of4:163-bit: 0x29, 233-bit: 0x3B, 283-bit: 0x47,409-bit: 0x67, 571-bit: 0x8F
0x7F8 HSM_PKA_GF2M_OPTIONS access per field reset 0x23C0044 — GF2m module options register.
  [31:28] RESERVED_2 wo — These bits should be written with zeroes and ignored on a read.
  [27:16] OPERAND_SIZE ro — Operand size. Represents the width of the operand registers inside the GF2m Engine. Value 0x23c means that the operand registers are 572 bits wide. The operand registers are one bit wider than the maximum supported filed size.
  [15:8] RESERVED_1 wo — These bits should be written with zeroes and ignored on a read.
  [7:4] MUL_DEPTH ro — Multiplier matrix depth. Represents the number of AND-XOR matrix rows implemented in the GF2m Engine. Value 0x4 means that multiplier matrix contains four levels of AND-XOR matrix rows.
  [3:0] OPERANDS ro — Number of implemented operand registers. Value 0x4 means four operands [A up to D].
0x7FC HSM_PKA_GF2M_VERSION access per field reset 0x2000000 — GF2m module version register.
  [31:28] RESERVED_2 wo — These bits should be written with zeroes and ignored on a read.
  [27:24] PATCH_LEVEL ro — These bits encode the hardware patch level of the GF2m Engine
  [23:20] MINOR_VERSION ro — These bits encode the minor version number of the GF2m Engine
  [19:16] MAJOR_VERSION ro — These bits encode the major version number of the GF2m Engine
  [15:0] RESERVED_1 wo — These bits should be written with zeroes and ignored on a read.
0x1FE0 HSM_PKA_PKA_REV ro reset 0x10 — Shell HW revision.
  [31:0] REVISION — The revision number of this EIP-29t2 module
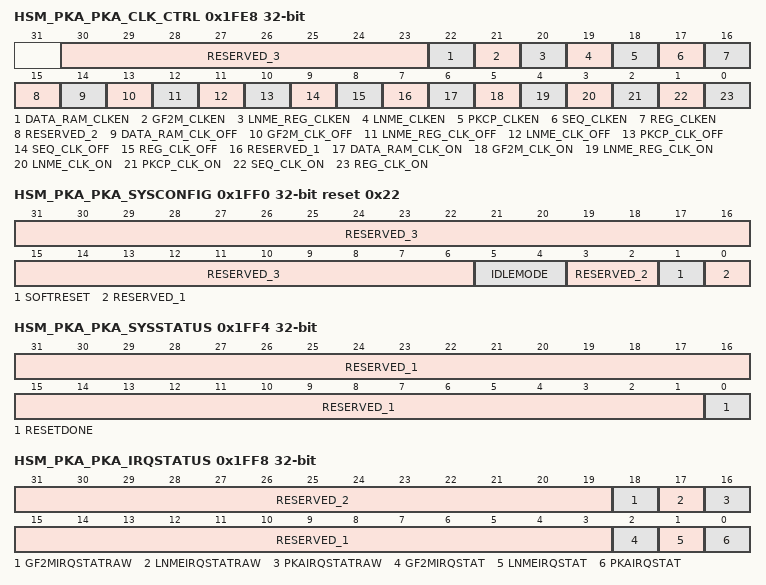
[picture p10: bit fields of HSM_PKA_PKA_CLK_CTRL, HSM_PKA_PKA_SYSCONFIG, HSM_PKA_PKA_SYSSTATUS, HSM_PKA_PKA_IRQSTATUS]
0x1FE8 HSM_PKA_PKA_CLK_CTRL access per field — PKA clock control.
  [30:23] RESERVED_3 wo — This bit should be written with zero and ignored on reads.
  [22] DATA_RAM_CLKEN rw — Clock enable status of data_ram_clk. The reset value of this bit is0bbut after reset, this bit is immediately refreshed with the actual clock
  [21] GF2M_CLKEN rw — Clock enable status of gf2m_clk.The reset value of this bit is0bbut after reset, this bit is immediately refreshed with the actual clock
  [20] LNME_REG_CLKEN rw — Clock enable status of lnme_reg_clk. The reset value of this bit is0bbut after reset, this bit is immediately refreshed with the actual clock
  [19] LNME_CLKEN rw — Clock enable status of lnme_clk. The reset value of this bit is0bbut after reset, this bit is immediately refreshed with the actual clock
  [18] PKCP_CLKEN rw — Clock enable status of pkcp_clk.The reset value of this bit is0bbut after reset, this bit is immediately refreshed with the actual clock
  [17] SEQ_CLKEN rw — Clock enable status of seq_clk. The reset value of this bit is0bbut after reset, this bit is immediately refreshed with the actual clock
  [16] REG_CLKEN rw — Clock enable status of reg_clk. The reset value of this bit is0bbut after reset, this bit is immediately refreshed with the actual clock
  [15] RESERVED_2 wo — This bit should be written with zero and ignored on reads.
  [14] DATA_RAM_CLK_OFF rw — Force data_ram_clk OFF
  [13] GF2M_CLK_OFF rw — Force gf2m_clk OFF
  [12] LNME_REG_CLK_OFF rw — Force lnme_reg_clk OFF
  [11] LNME_CLK_OFF rw — Force lnme_clk OFF
  [10] PKCP_CLK_OFF rw — Force pkcp_clk OFF
  [9] SEQ_CLK_OFF rw — Force seq_clk OFF
  [8] REG_CLK_OFF rw — Force reg_clk OFF
  [7] RESERVED_1 wo — This bit should be written with zero and ignored on reads.
  [6] DATA_RAM_CLK_ON rw — Force data_ram_clk ON
  [5] GF2M_CLK_ON rw — Force gf2m_clk ON
  [4] LNME_REG_CLK_ON rw — Force lnme_reg_clk ON
  [3] LNME_CLK_ON rw — Force lnme_clk ON
  [2] PKCP_CLK_ON rw — Force pkcp_clk ON
  [1] SEQ_CLK_ON rw — Force seq_clk ON
  [0] REG_CLK_ON rw — Force reg_clk ON
0x1FF0 HSM_PKA_PKA_SYSCONFIG access per field reset 0x22 — Shell configuration.
  [31:6] RESERVED_3 wo — This bit should be written with zero and ignored on reads.
  [5:4] IDLEMODE rw — Selects the module Idle mode. These bit combinations are only available: 00 = Force Idle mode: An IdleRequest is immediately acknowledged., 01 = No Idle mode: An IdleRequest is never acknowledged., 10 = Smart Idle mode: An IdleRequest is not acknowledged until the module is done processing [reset default]., 11 = Reserved
  [3:2] RESERVED_2 wo — This bit should be written with zero and ignored on reads.
  [1] SOFTRESET ro — If set to 1, the soft reset sequence is applied to the module.
  [0] RESERVED_1 wo — This bit should be written with zero and ignored on reads.
0x1FF4 HSM_PKA_PKA_SYSSTATUS access per field — Shell status.
  [31:1] RESERVED_1 wo — These bits should be written with zero and ignored on reads.
  [0] RESETDONE ro — When this bit reads1b the module reset is completed.
0x1FF8 HSM_PKA_PKA_IRQSTATUS access per field — Interrupt status.
  [31:19] RESERVED_2 wo — These bits should not be written and ignored on reads.
  [18] GF2MIRQSTATRAW ro — Raw GF2m Engine ready interrupt status. Note: The reset value of this bit is0b but this bit becomes1bdirectly after reset.
  [17] LNMEIRQSTATRAW ro — Raw combined LNME0 & LNME1 ready interrupt status. Note: The reset value of this bit is0b but this bit becomes1bdirectly after reset.
  [16] PKAIRQSTATRAW ro — Raw main PKA interrupt status. The reset value of this bit is zero, but it will become high after a few cycles, to indicate that the PKA is ready to be used. For the Program ROM configuration this is within a few cycles after a reset, for the Program RAM configuration a few cycles after pulling the Sequencer out of reset [section 8.3.2], provided the firmware is loaded in Program RAM prior to that.
  [15:3] RESERVED_1 wo — These bits should not be written and ignored on reads.
  [2] GF2MIRQSTAT ro — Masked GF2m Engine ready interrupt status.This interrupt can be enbled when setting the GF2mIrqEn bit in the PKA_IRQENABLE register. This interrupt can be cleared by Writing this bit. Writing1bclears the GF2m Engine ready interrupt.This bit is self-clearing; it does not have to be set to0bafterwards. Writing0bhas no effect.
  [1] LNMEIRQSTAT ro — Masked combined LNME0 & LNME1 ready interrupt status.This interrupt can be enbled when setting the LNMEIrqEn bit in the PKA_IRQENABLE register. This interrupt can be cleared by Writing this bit. Writing1bclears the combined LNME0 & LNME1 ready interrupt. This bit is self-clearing; it does not have to be set to0bafterwards. Writing0bhas no effect.
  [0] PKAIRQSTAT ro — Masked main PKA interrupt status.This interrupt can be enbled when setting the PkaIrqEn bit in the PKA_IRQENABLE register. This interrupt can be cleared by Writing this bit. Writing1bclears the main PKA interrupt. This bit is self-clearing; it does not have to be set to0bafterwards. Writing0bhas no effect.
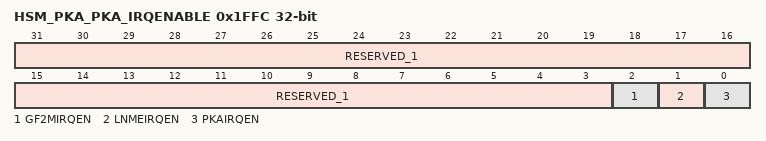
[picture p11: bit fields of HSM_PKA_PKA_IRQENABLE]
0x1FFC HSM_PKA_PKA_IRQENABLE wo — Interrupt enable.
  [31:3] RESERVED_1 — These bits should not be written and ignored on reads.
  [2] GF2MIRQEN — Enable the GF2m Engine interrupt.
  [1] LNMEIRQEN — Enable the combined LNME0 & LNME1 ready interrupt
  [0] PKAIRQEN — Enable the PKA interrupt.
